# FM33LE0XXA register map
File version: 1.0
CPU: SC000 r1p0, little endian, no MPU, no FPU, 3 interrupt priority bits
Registers are 32-bit, read-write, reset 0x0 unless marked. A register's access mark holds for its fields unless they carry their own. Offsets are from the block's base; [hi:lo] are bit positions.

## COMP — COMP module information
Base 0x4001A870
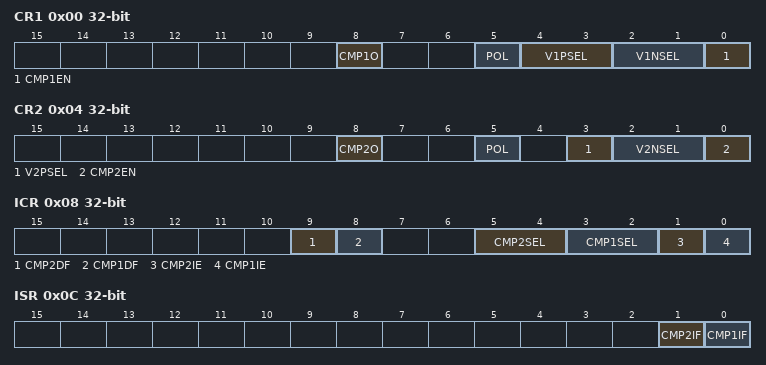
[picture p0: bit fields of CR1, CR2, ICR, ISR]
0x00 CR1 access per field — ComparatorControl Register 1
  [8] CMP1O ro — CMP1O field description
  [5] POL rw — POL field description
  [4:3] V1PSEL rw — V1PSEL field description
  [2:1] V1NSEL rw — V1NSEL field description
  [0] CMP1EN rw — CMP1EN field description
0x04 CR2 access per field — Comparator Control Register 2
  [8] CMP2O ro — CMP2O field description
  [5] POL rw — POL field description
  [3] V2PSEL rw — V2PSEL field description
  [2:1] V2NSEL rw — V2NSEL field description
  [0] CMP2EN rw — CMP2EN field description
0x08 ICR — Comparator Interrupt Config Register
  [9] CMP2DF — CMP2DF field description
  [8] CMP1DF — CMP1DF field description
  [5:4] CMP2SEL — CMP2SEL field description
  [3:2] CMP1SEL — CMP1SEL field description
  [1] CMP2IE — CMP2IE field description
  [0] CMP1IE — CMP1IE field description
0x0C ISR — Comparator Interrupt Status Register
  [1] CMP2IF — CMP2IF field description
  [0] CMP1IF — CMP1IF field description

## HDIV — HDIV module information
Base 0x40019000
0x00 END — Dividend Register
  [31:0] DIVEND — DIVEND field description
0x04 SOR — Divisor Regsiter
  [15:0] DIVSOR — DIVSOR field description
0x08 QUOT ro — Quotient Register
  [31:0] QUOT — QUOT field description
0x0C REMD ro — Reminder Register
  [15:0] REMD — REMD field description
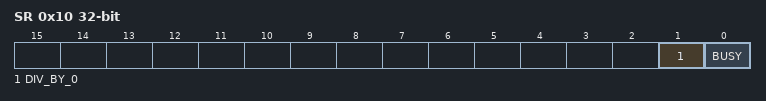
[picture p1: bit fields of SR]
0x10 SR ro — Status Register
  [1] DIV_BY_0 — DIV_BY_0 field description
  [0] BUSY — BUSY field description

## I2CSMB — I2CSMB module information
Base 0x40012800
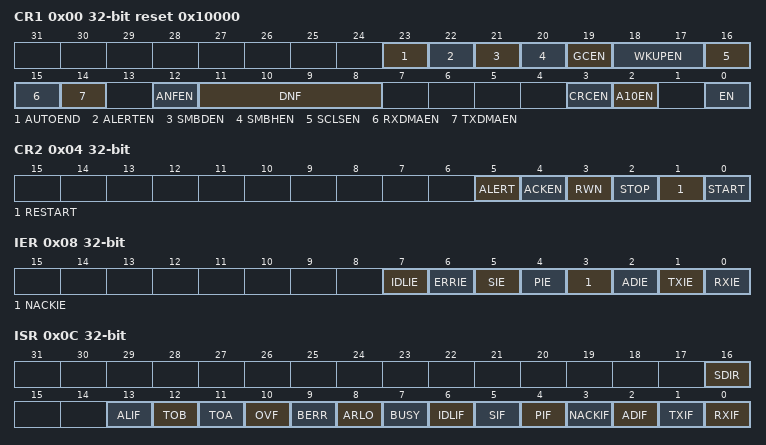
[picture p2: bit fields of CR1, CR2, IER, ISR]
0x00 CR1 reset 0x10000 — I2C SMBus Control Register
  [23] AUTOEND — AUTOEND field description
  [22] ALERTEN — ALERTEN field description
  [21] SMBDEN — SMBDEN field description
  [20] SMBHEN — SMBHEN field description
  [19] GCEN — GCEN field description
  [18:17] WKUPEN — WKUPEN field description
  [16] SCLSEN — SCLSEN field description
  [15] RXDMAEN — RXDMAEN field description
  [14] TXDMAEN — TXDMAEN field description
  [12] ANFEN — ANFEN field description
  [11:8] DNF — DNF field description
  [3] CRCEN — CRCEN field description
  [2] A10EN — A10EN field description
  [0] EN — EN field description
0x04 CR2 — I2C SMBus Control Register
  [5] ALERT — ALERT field description
  [4] ACKEN — ACKEN field description
  [3] RWN — RWN field description
  [2] STOP — STOP field description
  [1] RESTART — RESTART field description
  [0] START — START field description
0x08 IER — I2C SMBus Intterupt Enable Register
  [7] IDLIE — IDLIE field description
  [6] ERRIE — ERRIE field description
  [5] SIE — SIE field description
  [4] PIE — PIE field description
  [3] NACKIE — NACKIE field description
  [2] ADIE — ADIE field description
  [1] TXIE — TXIE field description
  [0] RXIE — RXIE field description
0x0C ISR access per field — I2C Master Interrupt Status Register
  [16] SDIR ro — SDIR field description
  [13] ALIF rw — ALIF field description
  [12] TOB rw — TOB field description
  [11] TOA rw — TOA field description
  [10] OVF rw — OVF field description
  [9] BERR rw — BERR field description
  [8] ARLO rw — ARLO field description
  [7] BUSY ro — BUSY field description
  [6] IDLIF rw — IDLIF field description
  [5] SIF rw — SIF field description
  [4] PIF rw — PIF field description
  [3] NACKIF rw — NACKIF field description
  [2] ADIF rw — ADIF field description
  [1] TXIF rw — TXIF field description
  [0] RXIF rw — RXIF field description
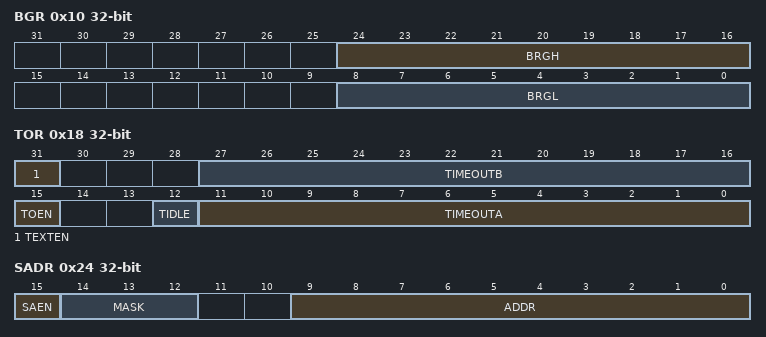
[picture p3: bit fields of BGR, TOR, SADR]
0x10 BGR
  [24:16] BRGH — BRGH field description
  [8:0] BRGL — BRGL field description
0x14 TIMINGR
  [8:0] SDAHD — SDAHD field description
0x18 TOR
  [31] TEXTEN — TEXTEN field description
  [27:16] TIMEOUTB — TIMEOUTB field description
  [15] TOEN — TOEN field description
  [12] TIDLE — TIDLE field description
  [11:0] TIMEOUTA — TIMEOUTA field description
0x1C RXDR ro
  [7:0] RXDATA — RXDATA field description
0x20 TXDR
  [7:0] TXDATA — TXDATA field description
0x24 SADR
  [15] SAEN — SAEN field description
  [14:12] MASK — MASK field description
  [9:0] ADDR — ADDR field description
0x28 CRC_DR ro
  [7:0] DR — DR field description
0x2C CRC_LFSR
  [7:0] LFSR — LFSR field description
0x30 CRC_POLY
  [7:0] POLY — POLY field description
